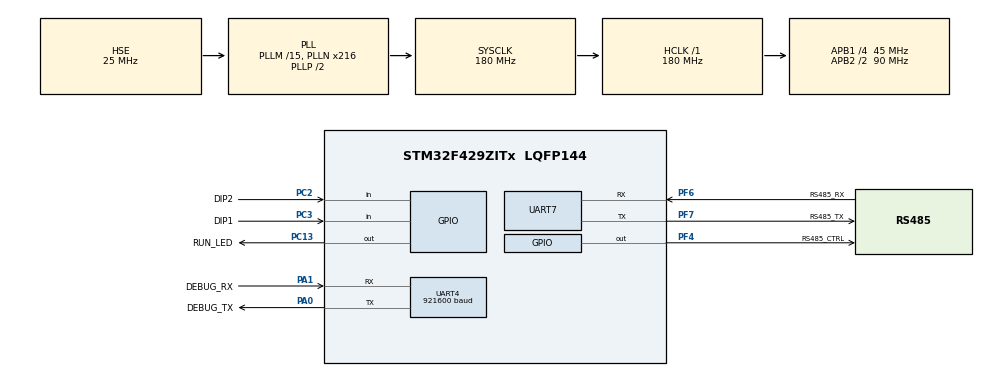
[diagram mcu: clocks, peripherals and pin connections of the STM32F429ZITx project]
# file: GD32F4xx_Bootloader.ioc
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Mcu.Family=STM32F4
Mcu.Name=STM32F429ZITx
Mcu.Package=LQFP144
NVIC.PriorityGroup=NVIC_PRIORITYGROUP_4
PA0/WKUP.GPIO_Label=DEBUG_TX
PA0/WKUP.Mode=Asynchronous
PA0/WKUP.Signal=UART4_TX
PA1.GPIO_Label=DEBUG_RX
PA1.Mode=Asynchronous
PA1.Signal=UART4_RX
PC13.GPIO_Label=RUN_LED
PC13.PinState=GPIO_PIN_SET
PC13.Signal=GPIO_Output
PC2.GPIO_Label=DIP2
PC2.Signal=GPIO_Input
PC3.GPIO_Label=DIP1
PC3.Signal=GPIO_Input
PF4.GPIO_Label=RS485_CTRL
PF4.Signal=GPIO_Output
PF6.GPIO_Label=RS485_RX
PF6.Mode=Asynchronous
PF6.Signal=UART7_RX
PF7.GPIO_Label=RS485_TX
PF7.Mode=Asynchronous
PF7.Signal=UART7_TX
PH0/OSC_IN.Mode=HSE-External-Oscillator
PH0/OSC_IN.Signal=RCC_OSC_IN
PH1/OSC_OUT.Mode=HSE-External-Oscillator
PH1/OSC_OUT.Signal=RCC_OSC_OUT
ProjectManager.HeapSize=0x200
ProjectManager.StackSize=0x400
ProjectManager.TargetToolchain=CMake
RCC.48MHZClocksFreq_Value=90000000
RCC.AHBFreq_Value=180000000
RCC.APB1CLKDivider=RCC_HCLK_DIV4
RCC.APB1Freq_Value=45000000
RCC.APB1TimFreq_Value=90000000
RCC.APB2CLKDivider=RCC_HCLK_DIV2
RCC.APB2Freq_Value=90000000
RCC.APB2TimFreq_Value=180000000
RCC.CortexFreq_Value=180000000
RCC.HCLKFreq_Value=180000000
RCC.HSE_VALUE=25000000
RCC.HSI_VALUE=16000000
RCC.LSE_VALUE=32768
RCC.PLLM=15
RCC.PLLN=216
RCC.PLLSourceVirtual=RCC_PLLSOURCE_HSE
RCC.SYSCLKFreq_VALUE=180000000
RCC.SYSCLKSource=RCC_SYSCLKSOURCE_PLLCLK
RCC.VCOOutputFreq_Value=360000000
UART4.BaudRate=921600
UART4.VirtualMode=Asynchronous
UART7.VirtualMode=Asynchronous
board=custom

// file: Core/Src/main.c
/* USER CODE BEGIN Header */
/**
 ******************************************************************************
 * @file           : main.c
 * @brief          : Main program body
 ******************************************************************************
 * @attention
 *
 * Copyright (c) 2025 STMicroelectronics.
 * All rights reserved.
 *
 * This software is licensed under terms that can be found in the LICENSE file
 * in the root directory of this software component.
 * If no LICENSE file comes with this software, it is provided AS-IS.
 *
 ******************************************************************************
 */
/* USER CODE END Header */
#include "main.h"
#include "usart.h"
#include "gpio.h"

/* USER CODE BEGIN Includes */
extern int boot_main(void);
/* USER CODE END Includes */

void SystemClock_Config(void);

int main(void)
{

  /* MCU Configuration--------------------------------------------------------*/

  /* Reset of all peripherals, Initializes the Flash interface and the Systick. */
  HAL_Init();

  /* Configure the system clock */
  SystemClock_Config();

  /* Initialize all configured peripherals */
  MX_GPIO_Init();
  MX_UART4_Init();
  MX_UART7_Init();
  /* USER CODE BEGIN 2 */
    boot_main();

  /* USER CODE END 2 */

  /* Infinite loop */
    while (1) {

    }
}

void SystemClock_Config(void)
{
  RCC_OscInitTypeDef RCC_OscInitStruct = {0};
  RCC_ClkInitTypeDef RCC_ClkInitStruct = {0};

  /** Configure the main internal regulator output voltage
  */
  __HAL_RCC_PWR_CLK_ENABLE();
  __HAL_PWR_VOLTAGESCALING_CONFIG(PWR_REGULATOR_VOLTAGE_SCALE1);

  /** Initializes the RCC Oscillators according to the specified parameters
  * in the RCC_OscInitTypeDef structure.
  */
  RCC_OscInitStruct.OscillatorType = RCC_OSCILLATORTYPE_HSE;
  RCC_OscInitStruct.HSEState = RCC_HSE_ON;
  RCC_OscInitStruct.PLL.PLLState = RCC_PLL_ON;
  RCC_OscInitStruct.PLL.PLLSource = RCC_PLLSOURCE_HSE;
  RCC_OscInitStruct.PLL.PLLM = 15;
  RCC_OscInitStruct.PLL.PLLN = 216;
  RCC_OscInitStruct.PLL.PLLP = RCC_PLLP_DIV2;
  RCC_OscInitStruct.PLL.PLLQ = 4;
  if (HAL_RCC_OscConfig(&RCC_OscInitStruct) != HAL_OK)
  {
    Error_Handler();
  }

  /** Activate the Over-Drive mode
  */
  if (HAL_PWREx_EnableOverDrive() != HAL_OK)
  {
    Error_Handler();
  }

  /** Initializes the CPU, AHB and APB buses clocks
  */
  RCC_ClkInitStruct.ClockType = RCC_CLOCKTYPE_HCLK|RCC_CLOCKTYPE_SYSCLK
                              |RCC_CLOCKTYPE_PCLK1|RCC_CLOCKTYPE_PCLK2;
  RCC_ClkInitStruct.SYSCLKSource = RCC_SYSCLKSOURCE_PLLCLK;
  RCC_ClkInitStruct.AHBCLKDivider = RCC_SYSCLK_DIV1;
  RCC_ClkInitStruct.APB1CLKDivider = RCC_HCLK_DIV4;
  RCC_ClkInitStruct.APB2CLKDivider = RCC_HCLK_DIV2;

  if (HAL_RCC_ClockConfig(&RCC_ClkInitStruct, FLASH_LATENCY_5) != HAL_OK)
  {
    Error_Handler();
  }
}

void Error_Handler(void)
{
  /* USER CODE BEGIN Error_Handler_Debug */
    /* User can add his own implementation to report the HAL error return state
     */
    __disable_irq();
    while (1) {
    }
  /* USER CODE END Error_Handler_Debug */
}
#ifdef USE_FULL_ASSERT
/**
  * @brief  Reports the name of the source file and the source line number
  *         where the assert_param error has occurred.
  * @param  file: pointer to the source file name
  * @param  line: assert_param error line source number
  * @retval None
  */
void assert_failed(uint8_t *file, uint32_t line)
{
  /* USER CODE BEGIN 6 */
    /* User can add his own implementation to report the file name and line
       number, ex: printf("Wrong parameters value: file %s on line %d\r\n",
       file, line) */
  /* USER CODE END 6 */
}
#endif /* USE_FULL_ASSERT */
